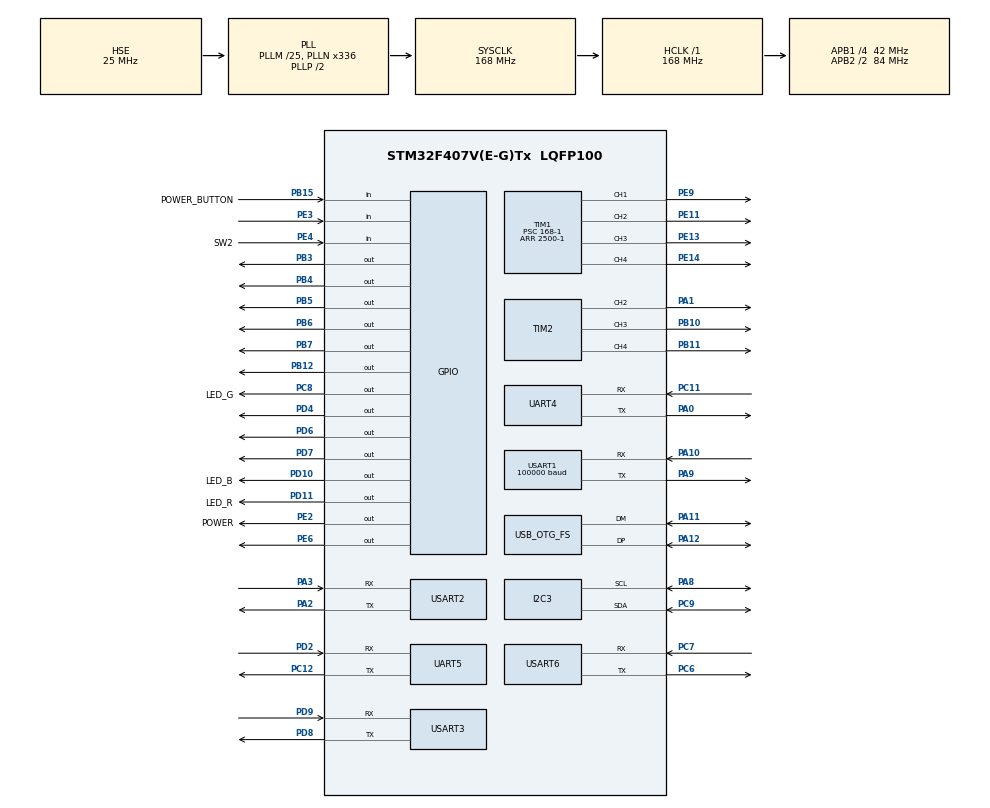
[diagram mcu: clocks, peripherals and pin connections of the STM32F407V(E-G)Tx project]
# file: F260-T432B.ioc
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Dma.Request0=UART4_TX
Dma.Request1=UART4_RX
Dma.Request10=UART5_RX
Dma.Request2=UART5_TX
Dma.Request3=USART2_TX
Dma.Request4=USART3_RX
Dma.Request5=USART6_RX
Dma.Request6=USART6_TX
Dma.Request7=USART3_TX
Dma.Request8=USART1_RX
Dma.Request9=USART2_RX
Dma.UART4_RX.1.Direction=DMA_PERIPH_TO_MEMORY
Dma.UART4_RX.1.FIFOMode=DMA_FIFOMODE_DISABLE
Dma.UART4_RX.1.Instance=DMA1_Stream2
Dma.UART4_RX.1.MemDataAlignment=DMA_MDATAALIGN_BYTE
Dma.UART4_RX.1.MemInc=DMA_MINC_ENABLE
Dma.UART4_RX.1.Mode=DMA_CIRCULAR
Dma.UART4_RX.1.PeriphDataAlignment=DMA_PDATAALIGN_BYTE
Dma.UART4_RX.1.PeriphInc=DMA_PINC_DISABLE
Dma.UART4_RX.1.Priority=DMA_PRIORITY_LOW
Dma.UART4_TX.0.Direction=DMA_MEMORY_TO_PERIPH
Dma.UART4_TX.0.FIFOMode=DMA_FIFOMODE_DISABLE
Dma.UART4_TX.0.Instance=DMA1_Stream4
Dma.UART4_TX.0.MemDataAlignment=DMA_MDATAALIGN_BYTE
Dma.UART4_TX.0.MemInc=DMA_MINC_ENABLE
Dma.UART4_TX.0.Mode=DMA_NORMAL
Dma.UART4_TX.0.PeriphDataAlignment=DMA_PDATAALIGN_BYTE
Dma.UART4_TX.0.PeriphInc=DMA_PINC_DISABLE
Dma.UART4_TX.0.Priority=DMA_PRIORITY_LOW
Dma.UART5_RX.10.Direction=DMA_PERIPH_TO_MEMORY
Dma.UART5_RX.10.FIFOMode=DMA_FIFOMODE_DISABLE
Dma.UART5_RX.10.Instance=DMA1_Stream0
Dma.UART5_RX.10.MemDataAlignment=DMA_MDATAALIGN_BYTE
Dma.UART5_RX.10.MemInc=DMA_MINC_ENABLE
Dma.UART5_RX.10.Mode=DMA_NORMAL
Dma.UART5_RX.10.PeriphDataAlignment=DMA_PDATAALIGN_BYTE
Dma.UART5_RX.10.PeriphInc=DMA_PINC_DISABLE
Dma.UART5_RX.10.Priority=DMA_PRIORITY_LOW
Dma.UART5_TX.2.Direction=DMA_MEMORY_TO_PERIPH
Dma.UART5_TX.2.FIFOMode=DMA_FIFOMODE_DISABLE
Dma.UART5_TX.2.Instance=DMA1_Stream7
Dma.UART5_TX.2.MemDataAlignment=DMA_MDATAALIGN_BYTE
Dma.UART5_TX.2.MemInc=DMA_MINC_ENABLE
Dma.UART5_TX.2.Mode=DMA_NORMAL
Dma.UART5_TX.2.PeriphDataAlignment=DMA_PDATAALIGN_BYTE
Dma.UART5_TX.2.PeriphInc=DMA_PINC_DISABLE
Dma.UART5_TX.2.Priority=DMA_PRIORITY_LOW
Dma.USART1_RX.8.Direction=DMA_PERIPH_TO_MEMORY
Dma.USART1_RX.8.FIFOMode=DMA_FIFOMODE_DISABLE
Dma.USART1_RX.8.Instance=DMA2_Stream2
Dma.USART1_RX.8.MemDataAlignment=DMA_MDATAALIGN_BYTE
Dma.USART1_RX.8.MemInc=DMA_MINC_ENABLE
Dma.USART1_RX.8.Mode=DMA_NORMAL
Dma.USART1_RX.8.PeriphDataAlignment=DMA_PDATAALIGN_BYTE
Dma.USART1_RX.8.PeriphInc=DMA_PINC_DISABLE
Dma.USART1_RX.8.Priority=DMA_PRIORITY_LOW
Dma.USART2_RX.9.Direction=DMA_PERIPH_TO_MEMORY
Dma.USART2_RX.9.FIFOMode=DMA_FIFOMODE_DISABLE
Dma.USART2_RX.9.Instance=DMA1_Stream5
Dma.USART2_RX.9.MemDataAlignment=DMA_MDATAALIGN_BYTE
Dma.USART2_RX.9.MemInc=DMA_MINC_ENABLE
Dma.USART2_RX.9.Mode=DMA_NORMAL
Dma.USART2_RX.9.PeriphDataAlignment=DMA_PDATAALIGN_BYTE
Dma.USART2_RX.9.PeriphInc=DMA_PINC_DISABLE
Dma.USART2_RX.9.Priority=DMA_PRIORITY_LOW
Dma.USART2_TX.3.Direction=DMA_MEMORY_TO_PERIPH
Dma.USART2_TX.3.FIFOMode=DMA_FIFOMODE_DISABLE
Dma.USART2_TX.3.Instance=DMA1_Stream6
Dma.USART2_TX.3.MemDataAlignment=DMA_MDATAALIGN_BYTE
Dma.USART2_TX.3.MemInc=DMA_MINC_ENABLE
Dma.USART2_TX.3.Mode=DMA_NORMAL
Dma.USART2_TX.3.PeriphDataAlignment=DMA_PDATAALIGN_BYTE
Dma.USART2_TX.3.PeriphInc=DMA_PINC_DISABLE
Dma.USART2_TX.3.Priority=DMA_PRIORITY_LOW
Dma.USART3_RX.4.Direction=DMA_PERIPH_TO_MEMORY
Dma.USART3_RX.4.FIFOMode=DMA_FIFOMODE_DISABLE
Dma.USART3_RX.4.Instance=DMA1_Stream1
Dma.USART3_RX.4.MemDataAlignment=DMA_MDATAALIGN_BYTE
Dma.USART3_RX.4.MemInc=DMA_MINC_ENABLE
Dma.USART3_RX.4.Mode=DMA_CIRCULAR
Dma.USART3_RX.4.PeriphDataAlignment=DMA_PDATAALIGN_BYTE
Dma.USART3_RX.4.PeriphInc=DMA_PINC_DISABLE
Dma.USART3_RX.4.Priority=DMA_PRIORITY_LOW
Dma.USART3_TX.7.Direction=DMA_MEMORY_TO_PERIPH
Dma.USART3_TX.7.FIFOMode=DMA_FIFOMODE_DISABLE
Dma.USART3_TX.7.Instance=DMA1_Stream3
Dma.USART3_TX.7.MemDataAlignment=DMA_MDATAALIGN_BYTE
Dma.USART3_TX.7.MemInc=DMA_MINC_ENABLE
Dma.USART3_TX.7.Mode=DMA_NORMAL
Dma.USART3_TX.7.PeriphDataAlignment=DMA_PDATAALIGN_BYTE
Dma.USART3_TX.7.PeriphInc=DMA_PINC_DISABLE
Dma.USART3_TX.7.Priority=DMA_PRIORITY_LOW
Dma.USART6_RX.5.Direction=DMA_PERIPH_TO_MEMORY
Dma.USART6_RX.5.FIFOMode=DMA_FIFOMODE_DISABLE
Dma.USART6_RX.5.Instance=DMA2_Stream1
Dma.USART6_RX.5.MemDataAlignment=DMA_MDATAALIGN_BYTE
Dma.USART6_RX.5.MemInc=DMA_MINC_ENABLE
Dma.USART6_RX.5.Mode=DMA_CIRCULAR
Dma.USART6_RX.5.PeriphDataAlignment=DMA_PDATAALIGN_BYTE
Dma.USART6_RX.5.PeriphInc=DMA_PINC_DISABLE
Dma.USART6_RX.5.Priority=DMA_PRIORITY_LOW
Dma.USART6_TX.6.Direction=DMA_MEMORY_TO_PERIPH
Dma.USART6_TX.6.FIFOMode=DMA_FIFOMODE_DISABLE
Dma.USART6_TX.6.Instance=DMA2_Stream6
Dma.USART6_TX.6.MemDataAlignment=DMA_MDATAALIGN_BYTE
Dma.USART6_TX.6.MemInc=DMA_MINC_ENABLE
Dma.USART6_TX.6.Mode=DMA_NORMAL
Dma.USART6_TX.6.PeriphDataAlignment=DMA_PDATAALIGN_BYTE
Dma.USART6_TX.6.PeriphInc=DMA_PINC_DISABLE
Dma.USART6_TX.6.Priority=DMA_PRIORITY_LOW
Mcu.Family=STM32F4
Mcu.Name=STM32F407V(E-G)Tx
Mcu.Package=LQFP100
NVIC.DMA1_Stream0_IRQn=true\:0\:0\:false\:false\:true\:false\:true
NVIC.DMA1_Stream1_IRQn=true\:0\:0\:false\:false\:true\:false\:true
NVIC.DMA1_Stream2_IRQn=true\:0\:0\:false\:false\:true\:false\:true
NVIC.DMA1_Stream3_IRQn=true\:0\:0\:false\:false\:true\:false\:true
NVIC.DMA1_Stream4_IRQn=true\:0\:0\:false\:true\:true\:1\:false\:true
NVIC.DMA1_Stream5_IRQn=true\:0\:0\:false\:false\:true\:false\:true
NVIC.DMA1_Stream6_IRQn=true\:0\:0\:false\:false\:true\:false\:true
NVIC.DMA1_Stream7_IRQn=true\:0\:0\:false\:false\:true\:false\:true
NVIC.DMA2_Stream1_IRQn=true\:0\:0\:false\:false\:true\:false\:true
NVIC.DMA2_Stream2_IRQn=true\:0\:0\:false\:false\:true\:false\:true
NVIC.DMA2_Stream6_IRQn=true\:0\:0\:false\:false\:true\:false\:true
NVIC.OTG_FS_IRQn=true\:0\:0\:false\:false\:true\:false\:true
NVIC.PriorityGroup=NVIC_PRIORITYGROUP_4
NVIC.TIM3_IRQn=true\:0\:0\:false\:false\:true\:true\:true
NVIC.TIM4_IRQn=true\:0\:0\:false\:false\:true\:true\:true
NVIC.UART4_IRQn=true\:0\:0\:false\:false\:true\:true\:true
NVIC.UART5_IRQn=true\:0\:0\:false\:false\:true\:true\:true
NVIC.USART1_IRQn=true\:0\:0\:false\:false\:true\:true\:true
NVIC.USART2_IRQn=true\:0\:0\:false\:false\:true\:true\:true
NVIC.USART3_IRQn=true\:0\:0\:false\:false\:true\:true\:true
NVIC.USART6_IRQn=true\:0\:0\:false\:false\:true\:true\:true
PA0-WKUP.Mode=Asynchronous
PA0-WKUP.Signal=UART4_TX
PA1.Signal=S_TIM2_CH2
PA10.Mode=Asynchronous
PA10.Signal=USART1_RX
PA11.Mode=Device_Only
PA11.Signal=USB_OTG_FS_DM
PA12.Mode=Device_Only
PA12.Signal=USB_OTG_FS_DP
PA13.Mode=Serial_Wire
PA13.Signal=SYS_JTMS-SWDIO
PA14.Mode=Serial_Wire
PA14.Signal=SYS_JTCK-SWCLK
PA2.Mode=Asynchronous
PA2.Signal=USART2_TX
PA3.Mode=Asynchronous
PA3.Signal=USART2_RX
PA8.Mode=I2C
PA8.Signal=I2C3_SCL
PA9.Mode=Asynchronous
PA9.Signal=USART1_TX
PB10.Signal=S_TIM2_CH3
PB11.Signal=S_TIM2_CH4
PB12.Signal=GPIO_Output
PB15.GPIO_Label=POWER_BUTTON
PB15.Signal=GPIO_Input
PB3.GPIO_ModeDefaultOutputPP=GPIO_MODE_OUTPUT_PP
PB3.GPIO_PuPd=GPIO_PULLUP
PB3.GPIO_Speed=GPIO_SPEED_FREQ_HIGH
PB3.PinState=GPIO_PIN_SET
PB3.Signal=GPIO_Output
PB4.GPIO_ModeDefaultOutputPP=GPIO_MODE_OUTPUT_PP
PB4.GPIO_PuPd=GPIO_PULLUP
PB4.GPIO_Speed=GPIO_SPEED_FREQ_HIGH
PB4.PinState=GPIO_PIN_SET
PB4.Signal=GPIO_Output
PB5.GPIO_ModeDefaultOutputPP=GPIO_MODE_OUTPUT_PP
PB5.GPIO_PuPd=GPIO_PULLUP
PB5.GPIO_Speed=GPIO_SPEED_FREQ_HIGH
PB5.PinState=GPIO_PIN_SET
PB5.Signal=GPIO_Output
PB6.Signal=GPIO_Output
PB7.Signal=GPIO_Output
PC11.Mode=Asynchronous
PC11.Signal=UART4_RX
PC12.Mode=Asynchronous
PC12.Signal=UART5_TX
PC6.Mode=Asynchronous
PC6.Signal=USART6_TX
PC7.Mode=Asynchronous
PC7.Signal=USART6_RX
PC8.GPIO_Label=LED_G
PC8.Signal=GPIO_Output
PC9.Mode=I2C
PC9.Signal=I2C3_SDA
PD10.GPIO_Label=LED_B
PD10.Signal=GPIO_Output
PD11.GPIO_Label=LED_R
PD11.Signal=GPIO_Output
PD2.Mode=Asynchronous
PD2.Signal=UART5_RX
PD4.Signal=GPIO_Output
PD6.GPIO_ModeDefaultOutputPP=GPIO_MODE_OUTPUT_PP
PD6.GPIO_PuPd=GPIO_PULLUP
PD6.GPIO_Speed=GPIO_SPEED_FREQ_HIGH
PD6.PinState=GPIO_PIN_SET
PD6.Signal=GPIO_Output
PD7.GPIO_ModeDefaultOutputPP=GPIO_MODE_OUTPUT_PP
PD7.GPIO_PuPd=GPIO_PULLUP
PD7.GPIO_Speed=GPIO_SPEED_FREQ_HIGH
PD7.PinState=GPIO_PIN_SET
PD7.Signal=GPIO_Output
PD8.Mode=Asynchronous
PD8.Signal=USART3_TX
PD9.Mode=Asynchronous
PD9.Signal=USART3_RX
PE11.Signal=S_TIM1_CH2
PE13.Signal=S_TIM1_CH3
PE14.Signal=S_TIM1_CH4
PE2.GPIO_Label=POWER
PE2.GPIO_PuPd=GPIO_PULLUP
PE2.Signal=GPIO_Output
PE3.Signal=GPIO_Input
PE4.GPIO_Label=SW2
PE4.GPIO_PuPd=GPIO_PULLUP
PE4.Signal=GPIO_Input
PE6.Signal=GPIO_Output
PE9.Signal=S_TIM1_CH1
PH0-OSC_IN.Mode=HSE-External-Oscillator
PH0-OSC_IN.Signal=RCC_OSC_IN
PH1-OSC_OUT.Mode=HSE-External-Oscillator
PH1-OSC_OUT.Signal=RCC_OSC_OUT
ProjectManager.HeapSize=0x200
ProjectManager.StackSize=0x200
ProjectManager.TargetToolchain=MDK-ARM V5
RCC.48MHZClocksFreq_Value=48000000
RCC.AHBFreq_Value=168000000
RCC.APB1CLKDivider=RCC_HCLK_DIV4
RCC.APB1Freq_Value=42000000
RCC.APB1TimFreq_Value=84000000
RCC.APB2CLKDivider=RCC_HCLK_DIV2
RCC.APB2Freq_Value=84000000
RCC.APB2TimFreq_Value=168000000
RCC.CortexFreq_Value=168000000
RCC.HCLKFreq_Value=168000000
RCC.HSE_VALUE=25000000
RCC.HSI_VALUE=16000000
RCC.LSE_VALUE=32768
RCC.PLLM=25
RCC.PLLN=336
RCC.PLLQ=7
RCC.SYSCLKFreq_VALUE=168000000
RCC.SYSCLKSource=RCC_SYSCLKSOURCE_PLLCLK
RCC.VCOOutputFreq_Value=336000000
SH.S_TIM1_CH1.0=TIM1_CH1,PWM Generation1 CH1
SH.S_TIM1_CH2.0=TIM1_CH2,PWM Generation2 CH2
SH.S_TIM1_CH3.0=TIM1_CH3,PWM Generation3 CH3
SH.S_TIM1_CH4.0=TIM1_CH4,PWM Generation4 CH4
SH.S_TIM2_CH2.0=TIM2_CH2,PWM Generation2 CH2
SH.S_TIM2_CH3.0=TIM2_CH3,PWM Generation3 CH3
SH.S_TIM2_CH4.0=TIM2_CH4,PWM Generation4 CH4
TIM1.Channel-PWM\ Generation1\ CH1=TIM_CHANNEL_1
TIM1.Channel-PWM\ Generation2\ CH2=TIM_CHANNEL_2
TIM1.Channel-PWM\ Generation3\ CH3=TIM_CHANNEL_3
TIM1.Channel-PWM\ Generation4\ CH4=TIM_CHANNEL_4
TIM1.Period=2500-1
TIM1.Prescaler=168-1
TIM1.Pulse-PWM\ Generation1\ CH1=1000
TIM1.Pulse-PWM\ Generation2\ CH2=1000
TIM1.Pulse-PWM\ Generation3\ CH3=1000
TIM1.Pulse-PWM\ Generation4\ CH4=1000
TIM2.Channel-PWM\ Generation2\ CH2=TIM_CHANNEL_2
TIM2.Channel-PWM\ Generation3\ CH3=TIM_CHANNEL_3
TIM2.Channel-PWM\ Generation4\ CH4=TIM_CHANNEL_4
TIM3.Period=1000-1
TIM3.Prescaler=168-1
TIM4.Period=1000
TIM4.Prescaler=168-1
UART4.VirtualMode=Asynchronous
UART5.VirtualMode=Asynchronous
USART1.BaudRate=100000
USART1.Parity=PARITY_EVEN
USART1.StopBits=STOPBITS_2
USART1.VirtualMode=VM_ASYNC
USART1.WordLength=WORDLENGTH_9B
USART2.VirtualMode=VM_ASYNC
USART3.VirtualMode=VM_ASYNC
USART6.VirtualMode=VM_ASYNC
USB_DEVICE.CLASS_NAME_FS=CDC
USB_DEVICE.MANUFACTURER_STRING-CDC_FS=ZKHD
USB_DEVICE.PRODUCT_STRING_CDC_FS=ZKHD
USB_DEVICE.VID-CDC_FS=0xffff
USB_DEVICE.VirtualMode-CDC_FS=Cdc
USB_DEVICE.VirtualModeFS=Cdc_FS
USB_OTG_FS.VirtualMode=Device_Only
VP_TIM3_VS_ClockSourceINT.Mode=Internal
VP_TIM4_VS_ClockSourceINT.Mode=Internal
VP_USB_DEVICE_VS_USB_DEVICE_CDC_FS.Mode=CDC_FS
board=custom

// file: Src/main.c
/* USER CODE BEGIN Header */
/**
  ******************************************************************************
  * @file           : main.c
  * @brief          : Main program body
  ******************************************************************************
  * @attention
  *
  * <h2><center>&copy; Copyright (c) 2021 STMicroelectronics.
  * All rights reserved.</center></h2>
  *
  * This software component is licensed by ST under Ultimate Liberty license
  * SLA0044, the "License"; You may not use this file except in compliance with
  * the License. You may obtain a copy of the License at:
  *                             www.st.com/SLA0044
  *
  ******************************************************************************
  */
/* USER CODE END Header */

#include "main.h"
#include "dma.h"
#include "i2c.h"
#include "tim.h"
#include "usart.h"
#include "usb_device.h"
#include "gpio.h"

/* USER CODE BEGIN Includes */
#include "include.h"
#include "UWB.h"
/* USER CODE END Includes */

/* USER CODE BEGIN PD */
#define time_1 500000
#define time_2 1000000
  static int  cnt = 0;
/* USER CODE END PD */

void SystemClock_Config(void);
static void MX_NVIC_Init(void);

/* USER CODE BEGIN 0 */
extern void Hadrware_Init(void);
/* USER CODE END 0 */

int main(void)
{

  /* MCU Configuration--------------------------------------------------------*/

  /* Reset of all peripherals, Initializes the Flash interface and the Systick. */
  HAL_Init();

  /* Configure the system clock */
  SystemClock_Config();

  /* Initialize all configured peripherals */
  MX_GPIO_Init();
  MX_DMA_Init();
  MX_TIM1_Init();
  MX_UART4_Init();
  MX_UART5_Init();
  MX_USART2_UART_Init();
  MX_USART3_UART_Init();
  MX_USART6_UART_Init();
  MX_USB_DEVICE_Init();
  MX_I2C3_Init();
  MX_TIM2_Init();
  MX_TIM3_Init();
  MX_USART1_UART_Init();
  MX_TIM4_Init();

  /* Initialize interrupts */
  MX_NVIC_Init();
  /* USER CODE BEGIN 2 */
  HAL_TIM_Base_Start(&htim2);
  HAL_TIM_PWM_Start(&htim2, TIM_CHANNEL_2);
  Hadrware_Init();
  uwb_init();
	//HAL_DeInit();
//	__HAL_UART_CLEAR_IDLEFLAG(&huart4);
//	__HAL_UART_ENABLE_IT(&huart4, UART_IT_IDLE);
  /* USER CODE END 2 */

  /* Infinite loop */
  while (1)
  {

    /* USER CODE BEGIN 3 */
      KernelPolling();

//	  if(cnt <= time_1)
//	  {
//		  __HAL_TIM_SetCompare(&htim2, TIM_CHANNEL_2, 1500);
//
//	  }

//	 if(cnt <=  time_2 && cnt > time_1)
//	  {
//		  __HAL_TIM_SetCompare(&htim2, TIM_CHANNEL_2, 600);
//
//	  }
//	  cnt++;
//	  if(cnt > time_2) cnt = 0;

  }
  /* USER CODE END 3 */
}

void SystemClock_Config(void)
{
  RCC_OscInitTypeDef RCC_OscInitStruct = {0};
  RCC_ClkInitTypeDef RCC_ClkInitStruct = {0};

  /** Configure the main internal regulator output voltage
  */
  __HAL_RCC_PWR_CLK_ENABLE();
  __HAL_PWR_VOLTAGESCALING_CONFIG(PWR_REGULATOR_VOLTAGE_SCALE1);
  /** Initializes the CPU, AHB and APB busses clocks
  */
  RCC_OscInitStruct.OscillatorType = RCC_OSCILLATORTYPE_HSE;
  RCC_OscInitStruct.HSEState = RCC_HSE_ON;
  RCC_OscInitStruct.PLL.PLLState = RCC_PLL_ON;
  RCC_OscInitStruct.PLL.PLLSource = RCC_PLLSOURCE_HSE;
  RCC_OscInitStruct.PLL.PLLM = 25;
  RCC_OscInitStruct.PLL.PLLN = 336;
  RCC_OscInitStruct.PLL.PLLP = RCC_PLLP_DIV2;
  RCC_OscInitStruct.PLL.PLLQ = 7;
  if (HAL_RCC_OscConfig(&RCC_OscInitStruct) != HAL_OK)
  {
    Error_Handler();
  }
  /** Initializes the CPU, AHB and APB busses clocks
  */
  RCC_ClkInitStruct.ClockType = RCC_CLOCKTYPE_HCLK|RCC_CLOCKTYPE_SYSCLK
                              |RCC_CLOCKTYPE_PCLK1|RCC_CLOCKTYPE_PCLK2;
  RCC_ClkInitStruct.SYSCLKSource = RCC_SYSCLKSOURCE_PLLCLK;
  RCC_ClkInitStruct.AHBCLKDivider = RCC_SYSCLK_DIV1;
  RCC_ClkInitStruct.APB1CLKDivider = RCC_HCLK_DIV4;
  RCC_ClkInitStruct.APB2CLKDivider = RCC_HCLK_DIV2;

  if (HAL_RCC_ClockConfig(&RCC_ClkInitStruct, FLASH_LATENCY_5) != HAL_OK)
  {
    Error_Handler();
  }
}

/**
  * @brief NVIC Configuration.
  * @retval None
  */
static void MX_NVIC_Init(void)
{
  /* DMA1_Stream4_IRQn interrupt configuration */
  HAL_NVIC_SetPriority(DMA1_Stream4_IRQn, 0, 0);
  HAL_NVIC_EnableIRQ(DMA1_Stream4_IRQn);
}

void Error_Handler(void)
{
}

/************************ (C) COPYRIGHT STMicroelectronics *****END OF FILE****/
